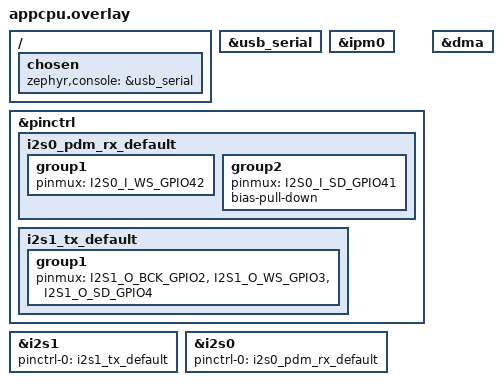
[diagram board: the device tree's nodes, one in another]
/*
 * Route APP CPU console to the same USB Serial/JTAG device as PRO CPU so
 * both cores' output appears on the same /dev/ttyACM0. The hardware FIFO
 * serialises concurrent writes; character-level interleaving is possible
 * under simultaneous heavy logging but acceptable for debug.
 */

#include <zephyr/dt-bindings/pinctrl/esp-pinctrl-common.h>
#include <zephyr/dt-bindings/pinctrl/esp32s3-gpio-sigmap.h>
#include <zephyr/dt-bindings/pinctrl/esp32s3-pinctrl.h>

/ {
	chosen {
		zephyr,console = &usb_serial;
	};
};

&usb_serial {
	status = "okay";
};

&ipm0 {
	status = "okay";
};

/*
 * PDM microphone — MSM261S4030H0R (built into XIAO ESP32S3 Sense)
 *   CLK  GPIO41 → I2S0_O_BCK (bit clock output, PDM clock)
 *   DATA GPIO42 → I2S0_I_SD  (input to ESP32, PDM data from mic)
 *
 * NOTE: If you get full-scale noise, these may be swapped on your board
 * revision. This overlay is the "GPIO41=CLK, GPIO42=DATA" variant.
 *
 * Pull-down on DATA (GPIO41): mono mic tri-states during CLK HIGH.
 * Pull-down holds the line LOW, making R-channel → near-zero DC.
 */
&pinctrl {
	i2s0_pdm_rx_default: i2s0_pdm_rx_default {
		group1 {
			/* Use O_* clock outputs (master mode). */
			pinmux = <I2S0_I_WS_GPIO42>;
		};
		group2 {
			pinmux = <I2S0_I_SD_GPIO41>;
			bias-pull-down;
		};
	};
};

/* DMA controller — shared by I2S0 (PDM RX) and I2S1 (speaker TX) */
&dma {
	status = "okay";
};

/*
 * I2S1 TX — MAX98357A Class D amplifier
 *   BCLK  GPIO2
 *   LRCLK GPIO3
 *   DOUT  GPIO4  (data out of ESP32 → DIN on MAX98357A)
 *
 * appcpu owns both I2S peripherals to avoid cross-core GDMA conflicts:
 * if procpu initialises its own I2S driver the GDMA global init corrupts
 * appcpu's I2S0 channel setup.
 */
&pinctrl {
	i2s1_tx_default: i2s1_tx_default {
		group1 {
			pinmux = <I2S1_O_BCK_GPIO2>,
				 <I2S1_O_WS_GPIO3>,
				 <I2S1_O_SD_GPIO4>;
		};
	};
};

&i2s1 {
	status = "okay";
	pinctrl-0 = <&i2s1_tx_default>;
	pinctrl-names = "default";
};

&i2s0 {
	status = "okay";
	pinctrl-0 = <&i2s0_pdm_rx_default>;
	pinctrl-names = "default";
};
